# SAMA7D65D1GN2 register map
Vendor: Microchip Technology; Series: SAMA7D6; File version: 0
Registers are 32-bit, read-write, reset 0x0 unless marked. A register's access mark holds for its fields unless they carry their own. Offsets are from the block's base; [hi:lo] are bit positions.

## GPU2DC — GPU 2D Controller
Base 0xE1480000
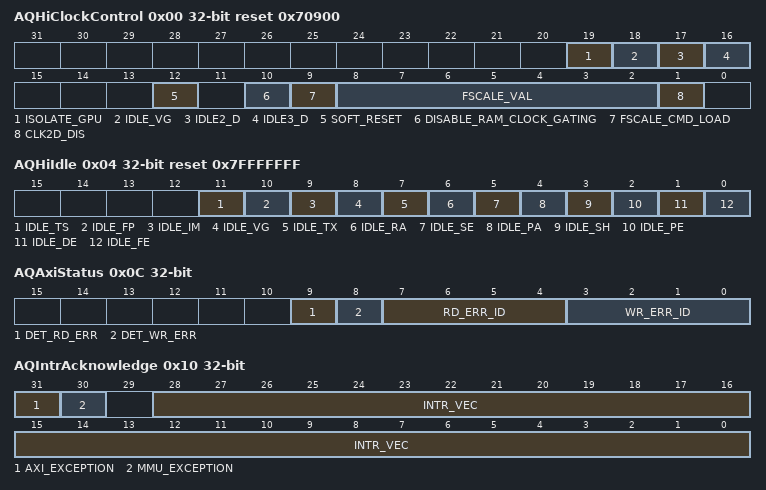
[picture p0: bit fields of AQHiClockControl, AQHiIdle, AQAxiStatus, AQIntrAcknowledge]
0x00 AQHiClockControl reset 0x70900 — Clock Control Register
  [19] ISOLATE_GPU
    0=FALSE (GPU2DC isolation is not active.); 1=TRUE (AXI interface is disabled and GPU2DC isolated.)
  [18] IDLE_VG — VG Pipe Idle
    0=FALSE (VG pipe is not idle.); 1=TRUE (VG pipe is idle)
  [17] IDLE2_D — 2D Pipe Idle
    0=ACTIVE (2D pipe is active.); 1=IDLE (2D pipe is idle.)
  [16] IDLE3_D — 3D Pipe Idle
    0=Not applicable, always read as '1'; 1=NOT_PRESENT (IDLE 3D pipe is not present)
  [12] SOFT_RESET — GPU2DC Software Reset
    0=Releases the soft reset; 1=Soft resets the module
  [10] DISABLE_RAM_CLOCK_GATING
    0=Functional clock gating is enabled for GPU2DC memories; 1=Functional clock gating is disabled for GPU2DC memories
  [9] FSCALE_CMD_LOAD — Core Clock Scaling Enable
    0=Clock scaling disabled; 1=Clock scaling enabled
  [8:2] FSCALE_VAL — Core Clock Frequency Scale Factor
  [1] CLK2D_DIS — Software Core Clock Disable
    0=Clock is enabled; 1=Clock is disabled
0x04 AQHiIdle ro reset 0x7FFFFFFF — Idle Status Register
  [11] IDLE_TS — TS Not Present
    0=Not applicable, always read as '1'
  [10] IDLE_FP — FP Not Present
    0=Not applicable, always read as '1'
  [9] IDLE_IM — IM Not Present
    0=Not applicable, always read as '1'
  [8] IDLE_VG — Vector Graphics Engine Not Present
    0=Not applicable, always read as '1'
  [7] IDLE_TX — Texture Engine Not Present
    0=Not applicable, always read as '1'
  [6] IDLE_RA — Raster Engine Not Present
    0=Not applicable, always read as '1'
  [5] IDLE_SE — Setup Engine Not Present
    0=Not applicable, always read as '1'
  [4] IDLE_PA — Primitive Assembly Not Present
    0=Not applicable, always read as '1'
  [3] IDLE_SH — Shader Engine Not Present
    0=Not applicable, always read as '1'
  [2] IDLE_PE — Pixel Engine Idle
    0=ACTIVE (Pixel engine is active.); 1=IDLE (Pixel engine is idle.)
  [1] IDLE_DE — Draw Engine Idle
    0=ACTIVE (Draw engine is active.); 1=IDLE (Draw engine is idle.)
  [0] IDLE_FE — Fetch Engine Idle
    0=ACTIVE (Fetch engine is active.); 1=IDLE (Fetch engine is idle.)
0x08 AQAxiConfig reset 0x2200 — AXI Configuration Register
  [8] AWCACHE — Set AWCACHE Value
    0=Non-bufferable bit; 1=Bufferable bit
0x0C AQAxiStatus ro — AXI Status Register
  [9] DET_RD_ERR — Detect Read Error
    0=No error; 1=Error detected on read
  [8] DET_WR_ERR — Detect Write Error
    0=No error; 1=Error detected on write
  [7:4] RD_ERR_ID — ReadID Caused Illegal Accesses
  [3:0] WR_ERR_ID — WriteID Caused Illegal Accesses
0x10 AQIntrAcknowledge ro — Interrupt Acknowledge Register
  [31] AXI_EXCEPTION
    0=No AXI exception; 1=AXI exception
  [30] MMU_EXCEPTION
    0=No MMU exception; 1=MMU exception
  [28:0] INTR_VEC — Event ID from ID28 to ID0
    0=Event IDx is not active; 1=Event IDx is active
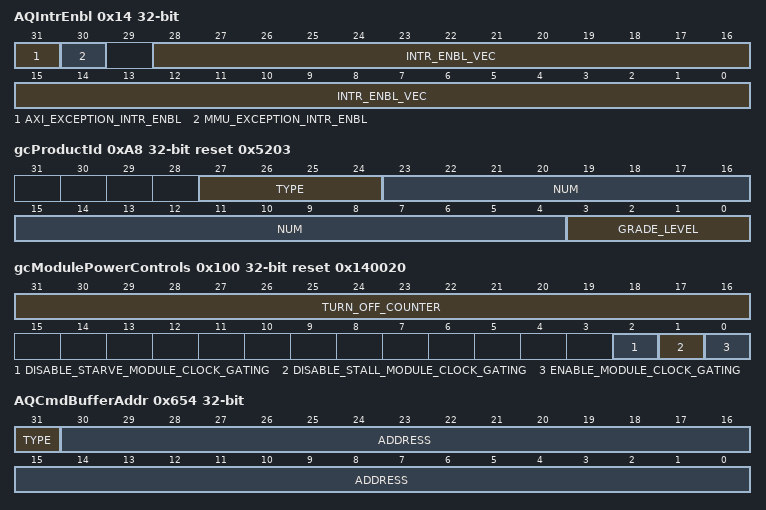
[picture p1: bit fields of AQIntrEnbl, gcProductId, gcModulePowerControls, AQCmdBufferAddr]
0x14 AQIntrEnbl — Interrupt Enable Register
  [31] AXI_EXCEPTION_INTR_ENBL — Interrupt Enable for an AXI Exception
  [30] MMU_EXCEPTION_INTR_ENBL — Interrupt Enable for an MMU Exception
  [28:0] INTR_ENBL_VEC
    0=Disables the interrupt for the corresponding event; 1=Enables the interrupt for the corresponding event
0xA8 gcProductId ro reset 0x5203 — Identification Register
  [27:24] TYPE
    0=2D and 3D graphics cores
  [23:4] NUM — Number
  [3:0] GRADE_LEVEL
0x100 gcModulePowerControls reset 0x140020 — Module Power Control Register
  [31:16] TURN_OFF_COUNTER
  [2] DISABLE_STARVE_MODULE_CLOCK_GATING — Module Level Clock Gating for Starve/Idle Condition Disable
    0=Disables module-level clock gating for starve/idle condition; 1=Enables module-level clock gating for starve/idle condition
  [1] DISABLE_STALL_MODULE_CLOCK_GATING — Module Level Clock Gating for Stall Condition Disable
    0=Disables module-level clock gating for stall condition; 1=Enables module-level clock gating for stall condition
  [0] ENABLE_MODULE_CLOCK_GATING — Module Level Clock Gating Enable
    0=Disables module-level clock gating; 1=Enables module-level clock gating
0x18C gcregMMUControl wo — MMU Control Register
  [0] ENABLE — MMU Enable
    0=No change in functionality. MMU remains as is.; 1=Enables the MMU. For security reasons, once the MMU has been enabled, it can be disabled only after a system reset.
0x414 AQMemoryDebug reset 0x3C000000 — Memory Debug Register
  [7:0] MAX_OUTSTANDING_READS — Maximum Number of Pending Read Transactions Allowed
0x654 AQCmdBufferAddr wo — Command Buffer Base Address Register
  [31] TYPE
    0=System; 1=Virtual system
  [30:0] ADDRESS — Base Address for the Command Buffer
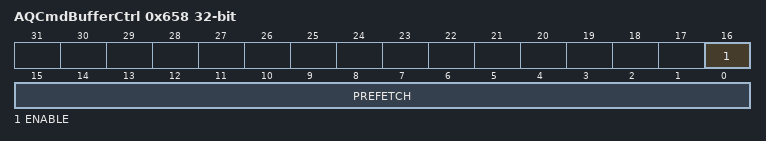
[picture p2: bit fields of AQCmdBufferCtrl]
0x658 AQCmdBufferCtrl wo — Command Buffer Base Control Register
  [16] ENABLE — Command Parser Enable
    0=Disables the command parser; 1=Enables the command parser
  [15:0] PREFETCH
0x664 AQFEDebugCurCmdAdr ro — Fetch Engine Debug Current Command Address Register
  [31:3] CUR_CMD_ADR — Current Command Address
